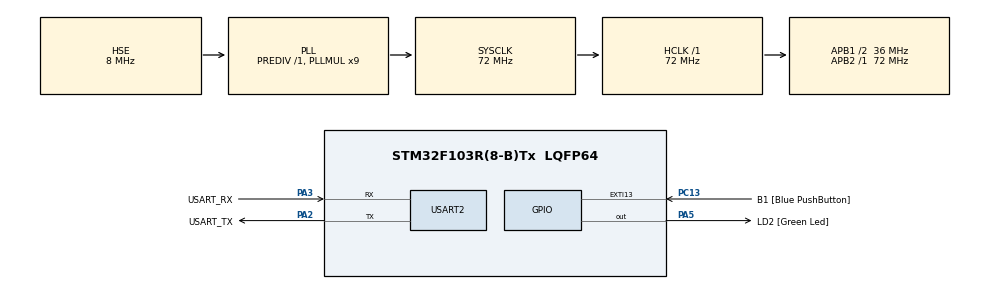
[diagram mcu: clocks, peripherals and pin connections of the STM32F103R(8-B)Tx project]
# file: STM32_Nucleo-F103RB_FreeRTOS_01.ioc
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FREERTOS.Tasks01=defaultTask,0,128,StartDefaultTask,Default,NULL,Dynamic,NULL,NULL
FREERTOS.configUSE_NEWLIB_REENTRANT=1
Mcu.Family=STM32F1
Mcu.Name=STM32F103R(8-B)Tx
Mcu.Package=LQFP64
NVIC.EXTI15_10_IRQn=true\:5\:0\:false\:false\:true\:true\:true\:true\:true
NVIC.PriorityGroup=NVIC_PRIORITYGROUP_4
NVIC.TIM1_UP_IRQn=true\:15\:0\:false\:false\:true\:false\:false\:true\:true
NVIC.TimeBase=TIM1_UP_IRQn
NVIC.TimeBaseIP=TIM1
PA13.GPIO_Label=TMS
PA13.Mode=Serial_Wire
PA13.Signal=SYS_JTMS-SWDIO
PA14.GPIO_Label=TCK
PA14.Mode=Serial_Wire
PA14.Signal=SYS_JTCK-SWCLK
PA2.GPIO_Label=USART_TX
PA2.GPIO_Mode=GPIO_MODE_AF_PP
PA2.GPIO_PuPd=GPIO_NOPULL
PA2.GPIO_Speed=GPIO_SPEED_FREQ_LOW
PA2.Mode=Asynchronous
PA2.Signal=USART2_TX
PA3.GPIO_Label=USART_RX
PA3.GPIO_Mode=GPIO_MODE_AF_PP
PA3.GPIO_PuPd=GPIO_NOPULL
PA3.GPIO_Speed=GPIO_SPEED_FREQ_LOW
PA3.Mode=Asynchronous
PA3.Signal=USART2_RX
PA5.GPIO_Label=LD2 [Green Led]
PA5.GPIO_ModeDefaultOutputPP=GPIO_MODE_OUTPUT_PP
PA5.GPIO_PuPd=GPIO_NOPULL
PA5.GPIO_Speed=GPIO_SPEED_FREQ_LOW
PA5.Signal=GPIO_Output
PB3.GPIO_Label=SWO
PB3.Signal=SYS_JTDO-TRACESWO
PC13-TAMPER-RTC.GPIO_Label=B1 [Blue PushButton]
PC13-TAMPER-RTC.GPIO_PuPd=GPIO_NOPULL
PC13-TAMPER-RTC.Signal=GPXTI13
PC14-OSC32_IN.Signal=RCC_OSC32_IN
PC15-OSC32_OUT.Signal=RCC_OSC32_OUT
PD0-OSC_IN.Mode=HSE-External-Oscillator
PD0-OSC_IN.Signal=RCC_OSC_IN
PD1-OSC_OUT.Mode=HSE-External-Oscillator
PD1-OSC_OUT.Signal=RCC_OSC_OUT
ProjectManager.HeapSize=0x200
ProjectManager.StackSize=0x400
ProjectManager.TargetToolchain=STM32CubeIDE
RCC.AHBFreq_Value=72000000
RCC.APB1CLKDivider=RCC_HCLK_DIV2
RCC.APB1Freq_Value=36000000
RCC.APB1TimFreq_Value=72000000
RCC.APB2Freq_Value=72000000
RCC.APB2TimFreq_Value=72000000
RCC.HCLKFreq_Value=72000000
RCC.PLLMUL=RCC_PLL_MUL9
RCC.PLLSourceVirtual=RCC_PLLSOURCE_HSE
RCC.RTCClockSelection=RCC_RTCCLKSOURCE_LSE
RCC.SYSCLKFreq_VALUE=72000000
RCC.SYSCLKSource=RCC_SYSCLKSOURCE_PLLCLK
RCC.USBFreq_Value=72000000
USART2.VirtualMode=VM_ASYNC
VP_FREERTOS_VS_CMSIS_V1.Mode=CMSIS_V1
VP_SYS_VS_tim1.Mode=TIM1
board=NUCLEO-F103RB

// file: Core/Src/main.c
/* ============================= main.c ============================= */

/* USER CODE BEGIN Header */
/**
  ******************************************************************************
  * @file           : main.c
  * @brief          : Main program body
  ******************************************************************************
  * @attention
  *
  * Copyright (c) 2025 STMicroelectronics.
  * All rights reserved.
  *
  * This software is licensed under terms that can be found in the LICENSE file
  * in the root directory of this software component.
  * If no LICENSE file comes with this software, it is provided AS-IS.
  *
  ******************************************************************************
  */
/* USER CODE END Header */

#include "main.h"
#include "cmsis_os.h"

/* USER CODE BEGIN Includes */
#include "config.h" // <<<<< [NOTE] – For blinking speed
/* USER CODE END Includes */

/* USER CODE BEGIN PTD */
// <<<<< [NOTE] – No custom typedefs for this simple demo
/* USER CODE END PTD */

/* USER CODE BEGIN PD */
// <<<<< [NOTE] – No #define macros required yet
/* USER CODE END PD */

/* USER CODE BEGIN PM */
// <<<<< [NOTE] – No private macros for now
/* USER CODE END PM */

UART_HandleTypeDef huart2;
/* USER CODE BEGIN PV */
// <<<<< [NOTE] – No additional private variables
/* USER CODE END PV */

void SystemClock_Config(void);
static void MX_GPIO_Init(void);
static void MX_USART2_UART_Init(void);
/* USER CODE BEGIN PFP */
// <<<<< [NOTE] – No extra prototypes
/* Forward declaration to call the RTOS init that lives in freertos.c */
void MX_FREERTOS_Init(void);
/* USER CODE END PFP */

/* USER CODE BEGIN 0 */
// <<<<< [NOTE] – Place for early-init code if you ever need it
/* USER CODE END 0 */

int main(void)
{
  /* USER CODE BEGIN 1 */
  // <<<<< [INIT] – Nothing special before HAL init
  /* USER CODE END 1 */

  /* MCU Configuration--------------------------------------------------------*/

  /* Reset of all peripherals, Initializes the Flash interface and the Systick. */
  HAL_Init();

  /* USER CODE BEGIN Init */
  // <<<<< [NOTE] – HAL already set up the tick timer
  /* USER CODE END Init */

  /* Configure the system clock */
  SystemClock_Config();

  /* USER CODE BEGIN SysInit */
  // <<<<< [NOTE] – System clock configured for 72 MHz (HSE + PLL×9)
  /* USER CODE END SysInit */

  /* Initialize all configured peripherals */
  MX_GPIO_Init();
  MX_USART2_UART_Init();

  /* USER CODE BEGIN 2 */
  // <<<<< [NOTE] – No peripheral-specific init beyond GPIO/UART
  /* USER CODE END 2 */

  /* USER CODE BEGIN RTOS_MUTEX */
  // <<<<< [NOTE] – No mutexes needed for the single-thread blink
  /* USER CODE END RTOS_MUTEX */

  /* USER CODE BEGIN RTOS_SEMAPHORES */
  // <<<<< [NOTE] – No semaphores needed
  /* USER CODE END RTOS_SEMAPHORES */

  /* USER CODE BEGIN RTOS_TIMERS */
  // <<<<< [NOTE] – No software timers used
  /* USER CODE END RTOS_TIMERS */

  /* USER CODE BEGIN RTOS_QUEUES */
  // <<<<< [NOTE] – No queues needed
  /* USER CODE END RTOS_QUEUES */

  /* Create the thread(s) in freertos.c */
  MX_FREERTOS_Init();    // <<<<< [RTOS] – All user tasks are created here

  /* Start scheduler */
  osKernelStart();

  /* We should never get here as control is now taken by the scheduler */
  /* Infinite loop */
  while (1)
  {

    /* USER CODE BEGIN 3 */
    // <<<<< [NOTE] – This loop is never reached; kept for safety
  }
  /* USER CODE END 3 */
}

void SystemClock_Config(void)
{
  RCC_OscInitTypeDef RCC_OscInitStruct = {0};
  RCC_ClkInitTypeDef RCC_ClkInitStruct = {0};

  /** Initializes the RCC Oscillators according to the specified parameters
    * in the RCC_OscInitTypeDef structure.
    */
  RCC_OscInitStruct.OscillatorType = RCC_OSCILLATORTYPE_HSE;
  RCC_OscInitStruct.HSEState       = RCC_HSE_ON;
  RCC_OscInitStruct.HSEPredivValue = RCC_HSE_PREDIV_DIV1;
  RCC_OscInitStruct.HSIState       = RCC_HSI_ON;
  RCC_OscInitStruct.PLL.PLLState   = RCC_PLL_ON;
  RCC_OscInitStruct.PLL.PLLSource  = RCC_PLLSOURCE_HSE;
  RCC_OscInitStruct.PLL.PLLMUL     = RCC_PLL_MUL9;
  if (HAL_RCC_OscConfig(&RCC_OscInitStruct) != HAL_OK)
  {
    Error_Handler();
  }

  /** Initializes the CPU, AHB and APB buses clocks
    */
  RCC_ClkInitStruct.ClockType      = RCC_CLOCKTYPE_HCLK|RCC_CLOCKTYPE_SYSCLK
                                   |RCC_CLOCKTYPE_PCLK1|RCC_CLOCKTYPE_PCLK2;
  RCC_ClkInitStruct.SYSCLKSource   = RCC_SYSCLKSOURCE_PLLCLK;
  RCC_ClkInitStruct.AHBCLKDivider  = RCC_SYSCLK_DIV1;
  RCC_ClkInitStruct.APB1CLKDivider = RCC_HCLK_DIV2;
  RCC_ClkInitStruct.APB2CLKDivider = RCC_HCLK_DIV1;
  if (HAL_RCC_ClockConfig(&RCC_ClkInitStruct, FLASH_LATENCY_2) != HAL_OK)
  {
    Error_Handler();
  }
}

static void MX_USART2_UART_Init(void)
{
  /* USER CODE BEGIN USART2_Init 0 */
  // <<<<< [NOTE] – No pre-init actions required
  /* USER CODE END USART2_Init 0 */

  /* USER CODE BEGIN USART2_Init 1 */
  // <<<<< [NOTE] – UART config matches the default console settings
  /* USER CODE END USART2_Init 1 */

  huart2.Instance          = USART2;
  huart2.Init.BaudRate     = 115200;
  huart2.Init.WordLength   = UART_WORDLENGTH_8B;
  huart2.Init.StopBits     = UART_STOPBITS_1;
  huart2.Init.Parity       = UART_PARITY_NONE;
  huart2.Init.Mode         = UART_MODE_TX_RX;
  huart2.Init.HwFlowCtl    = UART_HWCONTROL_NONE;
  huart2.Init.OverSampling = UART_OVERSAMPLING_16;
  if (HAL_UART_Init(&huart2) != HAL_OK)
  {
    Error_Handler();
  }

  /* USER CODE BEGIN USART2_Init 2 */
  // <<<<< [NOTE] – UART ready for debug prints (e.g., printf)
  /* USER CODE END USART2_Init 2 */
}

static void MX_GPIO_Init(void)
{
  GPIO_InitTypeDef GPIO_InitStruct = {0};

  /* USER CODE BEGIN MX_GPIO_Init_1 */
  // <<<<< [NOTE] – Enable clocks for all used ports
  /* USER CODE END MX_GPIO_Init_1 */

  /* GPIO Ports Clock Enable */
  __HAL_RCC_GPIOC_CLK_ENABLE();
  __HAL_RCC_GPIOD_CLK_ENABLE();
  __HAL_RCC_GPIOA_CLK_ENABLE();
  __HAL_RCC_GPIOB_CLK_ENABLE();

  /*Configure GPIO pin Output Level */
  HAL_GPIO_WritePin(LD2_GPIO_Port, LD2_Pin, GPIO_PIN_RESET);

  /*Configure GPIO pin : B1_Pin */
  GPIO_InitStruct.Pin  = B1_Pin;
  GPIO_InitStruct.Mode = GPIO_MODE_IT_RISING;
  GPIO_InitStruct.Pull = GPIO_NOPULL;
  HAL_GPIO_Init(B1_GPIO_Port, &GPIO_InitStruct);

  /*Configure GPIO pin : LD2_Pin */
  GPIO_InitStruct.Pin   = LD2_Pin;
  GPIO_InitStruct.Mode  = GPIO_MODE_OUTPUT_PP;
  GPIO_InitStruct.Pull  = GPIO_NOPULL;
  GPIO_InitStruct.Speed = GPIO_SPEED_FREQ_LOW;
  HAL_GPIO_Init(LD2_GPIO_Port, &GPIO_InitStruct);

  /* EXTI interrupt init */
  HAL_NVIC_SetPriority(EXTI15_10_IRQn, 5, 0);
  HAL_NVIC_EnableIRQ(EXTI15_10_IRQn);

  /* USER CODE BEGIN MX_GPIO_Init_2 */
  // <<<<< [NOTE] – No additional pins used in this demo
  /* USER CODE END MX_GPIO_Init_2 */
}

void HAL_TIM_PeriodElapsedCallback(TIM_HandleTypeDef *htim)
{
  /* USER CODE BEGIN Callback 0 */
  // <<<<< [NOTE] – No user code needed here for the blink demo
  /* USER CODE END Callback 0 */

  if (htim->Instance == TIM1)
  {
    HAL_IncTick();
  }

  /* USER CODE BEGIN Callback 1 */
  // <<<<< [NOTE] – Additional timer callbacks could be placed here
  /* USER CODE END Callback 1 */
}

void Error_Handler(void)
{
  /* USER CODE BEGIN Error_Handler_Debug */
  // <<<--- [ERROR] – Halt execution; replace with a watchdog reset if desired
  __disable_irq();
  while (1)
  {
  }
  /* USER CODE END Error_Handler_Debug */
}

#ifdef USE_FULL_ASSERT
/**
  * @brief  Reports the name of the source file and the source line number
  *         where the assert_param error has occurred.
  * @param  file: pointer to the source file name
  * @param  line: assert_param error line source number
  * @retval None
  */
void assert_failed(uint8_t *file, uint32_t line)
{
  /* USER CODE BEGIN 6 */
  // <<<--- [ASSERT] – You could print file/line via UART for debugging
  /* USER CODE END 6 */
}
#endif /* USE_FULL_ASSERT */

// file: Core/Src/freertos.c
/* =========================== freertos.c =========================== */

/* USER CODE BEGIN Header */
/**
  ******************************************************************************
  * @file           : freertos.c
  * @brief          : Code for freertos applications
  ******************************************************************************
  * @attention
  *
  * Copyright (c) 2025 STMicroelectronics.
  * All rights reserved.
  *
  * This software is licensed under terms that can be found in the LICENSE file
  * in the root directory of this software component.
  * If no LICENSE file comes with this software, it is provided AS-IS.
  *
  ******************************************************************************
  */
/* USER CODE END Header */

#include "FreeRTOS.h"
#include "task.h"
#include "main.h"

/* USER CODE BEGIN Includes */
#include "config.h"     // <<<<< [NOTE] – For blinking speed
#include "cmsis_os.h"   // <<<--- [NOTE] – Required for CMSIS-RTOS v1 API
/* USER CODE END Includes */

/* USER CODE BEGIN PTD */
// <<<--- [NOTE] – No custom typedefs needed for this simple example
/* USER CODE END PTD */

/* USER CODE BEGIN PD */
// <<<--- [NOTE] – No #define macros for now
/* USER CODE END PD */

/* USER CODE BEGIN PM */
// <<<--- [NOTE] – No private macros
/* USER CODE END PM */

/* USER CODE BEGIN Variables */
// <<<--- [NOTE] – No global variables besides those in main.c
/* USER CODE END Variables */

/* USER CODE BEGIN FunctionPrototypes */
// <<<--- [NOTE] – Prototypes for our blink task are below
void StartBlinkTask(void const * argument);
/* USER CODE END FunctionPrototypes */

/* GetIdleTaskMemory prototype (linked to static allocation support) */
void vApplicationGetIdleTaskMemory( StaticTask_t **ppxIdleTaskTCBBuffer,
                                    StackType_t **ppxIdleStackBuffer,
                                    uint32_t *pulIdleTaskStackSize );

/* USER CODE BEGIN GET_IDLE_TASK_MEMORY */
static StaticTask_t  xIdleTaskTCBBuffer;
static StackType_t   xIdleStack[configMINIMAL_STACK_SIZE];

void vApplicationGetIdleTaskMemory( StaticTask_t **ppxIdleTaskTCBBuffer,
                                    StackType_t **ppxIdleStackBuffer,
                                    uint32_t *pulIdleTaskStackSize )
{
  *ppxIdleTaskTCBBuffer = &xIdleTaskTCBBuffer;
  *ppxIdleStackBuffer   = &xIdleStack[0];
  *pulIdleTaskStackSize = configMINIMAL_STACK_SIZE;
  /* place for user code */
}
/* USER CODE END GET_IDLE_TASK_MEMORY */

/* USER CODE BEGIN Application */

/* -----------------------------------------------------------------------
   Blink task – toggles the on-board LED (LD2) every 500 ms.
   ----------------------------------------------------------------------- */
void StartBlinkTask(void const * argument)
{
  for (;;)
  {
    HAL_GPIO_TogglePin(LD2_GPIO_Port, LD2_Pin);   // <<<--- [BLINK] – toggle LED
    osDelay(BLINK_PERIOD_MS);                     // <<<--- [DELAY] – xxx ms pause
  }
}

/* -----------------------------------------------------------------------
   FreeRTOS initialization – creates the blink task.
   ----------------------------------------------------------------------- */
void MX_FREERTOS_Init(void)
{
  /* Thread definition for the blink task */
  osThreadDef(blinkTask, StartBlinkTask, osPriorityNormal, 0, 128);
  osThreadCreate(osThread(blinkTask), NULL);      // <<<--- [TASK] – start blinkTask
}
/* USER CODE END Application */
